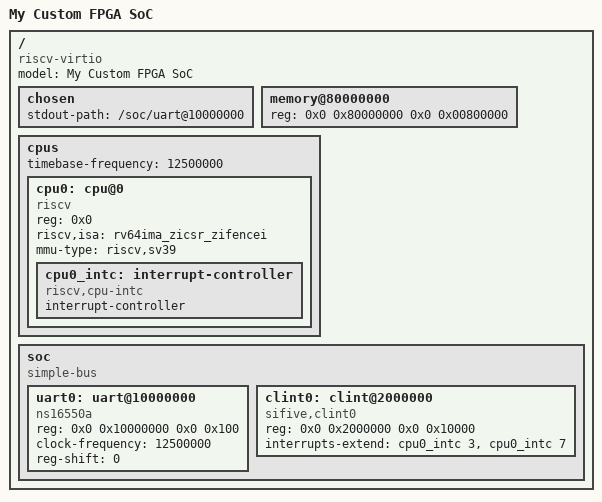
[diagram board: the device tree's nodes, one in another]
/dts-v1/;
/ {
   #address-cells = <2>;
   #size-cells = <2>;
   model = "My Custom FPGA SoC";
   compatible = "riscv-virtio";
 
   chosen {
       stdout-path = "/soc/uart@10000000";  // pass to opensbi
       //stdout-path = "/soc/uart@2004";  // pass to linux
   };
   
   memory@80000000 {
       device_type = "memory";
       //reg = <0x0 0x80000000 0x0 0x10000000>; /* 256MB RAM */  // two 32-bit value: high+low, address size
       reg = <0x0 0x80000000 0x0 0x00800000>; /* 8MB RAM */  // two 32-bit value: high+low, address size
   };

   cpus {
       #address-cells = <1>;
       #size-cells = <0>;
       timebase-frequency = <12500000>; // 12.5MHz
      
       cpu0: cpu@0 {
           device_type = "cpu";  // _ due to IEEE-1275
           reg = <0x0>;
           compatible = "riscv";
           riscv,isa = "rv64ima_zicsr_zifencei";
           mmu-type = "riscv,sv39";
  
           cpu0_intc: interrupt-controller {
               #interrupt-cells = <1>;
               interrupt-controller;
               compatible = "riscv,cpu-intc";
           };
        };
   };
  
   soc {  // a container for all mmp peripherals UART/Timers/SPI .etc
       #address-cells = <2>;
       #size-cells = <2>;
       compatible = "simple-bus";
       ranges; 

       //uart0: uart@2004{
       //    compatible = "sifive,uart0";
       //    reg = <0x0 0x2004 0x0 0x10>;
       //};
       //uart0: uart@10000000 {
       //    compatible = "altr,juart-1.0";
       //    reg = <0x0 0x10000000 0x0 0x8>;
       //};
       uart0: uart@10000000 {
           compatible = "ns16550a";
           reg = <0x0 0x10000000 0x0 0x100>;
           clock-frequency = <12500000>;
           reg-shift = <0>;
       };
       //timer@2004000 {
       //    compatible = "riscv,aclint-mtimer";
       //    reg = <0x0 0x2004000 0x0 0x8>,  // MTIMECMP addr
       //          <0x0 0x200BFF8 0x0 0x8>;  // MTIME addr
       //    interrupts-extend = <&cpu0_intc 7>; // TIP at 7
       //};
       //timer@2000000 {
       //    compatible = "riscv,clint0";
       //    reg = <0x0 0x2000000 0x0 0x10000>;
       //    interrupts-extend = <&cpu0_intc 3 &cpu0_intc 7>; // TIP at 7
       //};
       clint0: clint@2000000 {
           compatible = "sifive,clint0";
           reg = <0x0 0x2000000 0x0 0x10000>;
           interrupts-extend = <&cpu0_intc 3 &cpu0_intc 7>; // TIP at 7
       };
   };
};



















